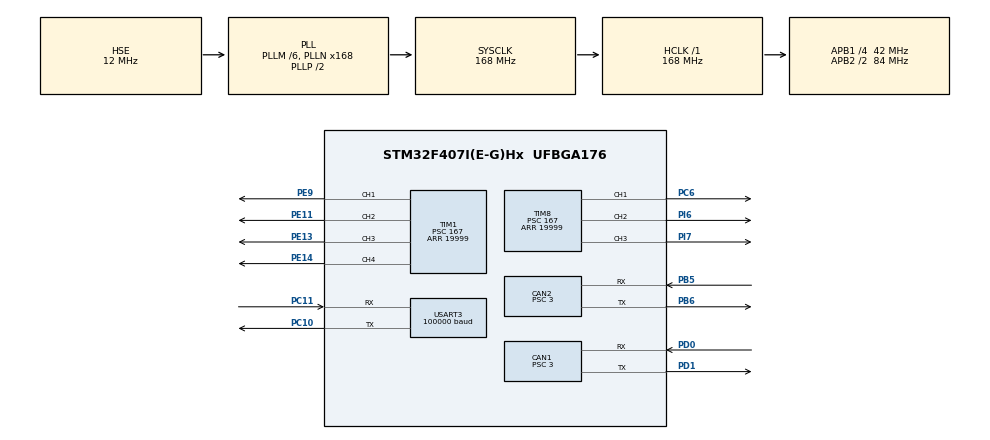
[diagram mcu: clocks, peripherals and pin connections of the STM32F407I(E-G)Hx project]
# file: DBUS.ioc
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CAN1.BS1=CAN_BS1_10TQ
CAN1.BS2=CAN_BS2_3TQ
CAN1.CalculateTimeQuantum=71.42857142857143
CAN1.Prescaler=3
CAN2.BS1=CAN_BS1_10TQ
CAN2.BS2=CAN_BS2_3TQ
CAN2.CalculateTimeQuantum=71.42857142857143
CAN2.Prescaler=3
Dma.Request0=USART3_RX
Dma.USART3_RX.0.Direction=DMA_PERIPH_TO_MEMORY
Dma.USART3_RX.0.FIFOMode=DMA_FIFOMODE_DISABLE
Dma.USART3_RX.0.Instance=DMA1_Stream1
Dma.USART3_RX.0.MemDataAlignment=DMA_MDATAALIGN_BYTE
Dma.USART3_RX.0.MemInc=DMA_MINC_ENABLE
Dma.USART3_RX.0.Mode=DMA_CIRCULAR
Dma.USART3_RX.0.PeriphDataAlignment=DMA_PDATAALIGN_BYTE
Dma.USART3_RX.0.PeriphInc=DMA_PINC_DISABLE
Dma.USART3_RX.0.Priority=DMA_PRIORITY_VERY_HIGH
FREERTOS.Tasks01=defaultTask,0,128,StartDefaultTask,Default,NULL,Dynamic,NULL,NULL
Mcu.Family=STM32F4
Mcu.Name=STM32F407I(E-G)Hx
Mcu.Package=UFBGA176
NVIC.CAN1_RX0_IRQn=true\:5\:0\:false\:false\:true\:true\:true\:true
NVIC.CAN2_RX0_IRQn=true\:5\:0\:false\:false\:true\:true\:true\:true
NVIC.DMA1_Stream1_IRQn=true\:5\:0\:false\:false\:true\:true\:false\:true
NVIC.PriorityGroup=NVIC_PRIORITYGROUP_4
NVIC.TIM2_IRQn=true\:0\:0\:false\:false\:true\:false\:false\:true
NVIC.TimeBase=TIM2_IRQn
NVIC.TimeBaseIP=TIM2
NVIC.USART3_IRQn=true\:5\:0\:false\:false\:false\:true\:true\:false
PA13.Mode=Serial_Wire
PA13.Signal=SYS_JTMS-SWDIO
PA14.Mode=Serial_Wire
PA14.Signal=SYS_JTCK-SWCLK
PB5.Mode=Slave
PB5.Signal=CAN2_RX
PB6.Mode=Slave
PB6.Signal=CAN2_TX
PC10.Mode=Asynchronous
PC10.Signal=USART3_TX
PC11.Mode=Asynchronous
PC11.Signal=USART3_RX
PC6.GPIO_PuPd=GPIO_PULLUP
PC6.GPIO_Speed=GPIO_SPEED_FREQ_HIGH
PC6.Signal=S_TIM8_CH1
PD0.Mode=Master
PD0.Signal=CAN1_RX
PD1.Mode=Master
PD1.Signal=CAN1_TX
PE11.GPIO_PuPd=GPIO_PULLUP
PE11.GPIO_Speed=GPIO_SPEED_FREQ_HIGH
PE11.Signal=S_TIM1_CH2
PE13.GPIO_PuPd=GPIO_PULLUP
PE13.GPIO_Speed=GPIO_SPEED_FREQ_HIGH
PE13.Signal=S_TIM1_CH3
PE14.GPIO_PuPd=GPIO_PULLUP
PE14.GPIO_Speed=GPIO_SPEED_FREQ_HIGH
PE14.Signal=S_TIM1_CH4
PE9.GPIO_PuPd=GPIO_PULLUP
PE9.GPIO_Speed=GPIO_SPEED_FREQ_HIGH
PE9.Signal=S_TIM1_CH1
PH0-OSC_IN.Mode=HSE-External-Oscillator
PH0-OSC_IN.Signal=RCC_OSC_IN
PH1-OSC_OUT.Mode=HSE-External-Oscillator
PH1-OSC_OUT.Signal=RCC_OSC_OUT
PI6.GPIO_PuPd=GPIO_PULLUP
PI6.GPIO_Speed=GPIO_SPEED_FREQ_HIGH
PI6.Signal=S_TIM8_CH2
PI7.GPIO_PuPd=GPIO_PULLUP
PI7.GPIO_Speed=GPIO_SPEED_FREQ_HIGH
PI7.Signal=S_TIM8_CH3
ProjectManager.HeapSize=0x2000
ProjectManager.StackSize=0x2000
ProjectManager.TargetToolchain=MDK-ARM V5
RCC.48MHZClocksFreq_Value=48000000
RCC.AHBFreq_Value=168000000
RCC.APB1CLKDivider=RCC_HCLK_DIV4
RCC.APB1Freq_Value=42000000
RCC.APB1TimFreq_Value=84000000
RCC.APB2CLKDivider=RCC_HCLK_DIV2
RCC.APB2Freq_Value=84000000
RCC.APB2TimFreq_Value=168000000
RCC.CortexFreq_Value=168000000
RCC.HCLKFreq_Value=168000000
RCC.HSE_VALUE=12000000
RCC.HSI_VALUE=16000000
RCC.LSE_VALUE=32768
RCC.PLLM=6
RCC.PLLN=168
RCC.PLLQ=7
RCC.PLLSourceVirtual=RCC_PLLSOURCE_HSE
RCC.RCC_RTC_Clock_SourceVirtual=RCC_RTCCLKSOURCE_HSE_DIV30
RCC.RCC_RTC_Clock_Source_FROM_HSE=RCC_RTCCLKSOURCE_HSE_DIV30
RCC.SYSCLKFreq_VALUE=168000000
RCC.SYSCLKSource=RCC_SYSCLKSOURCE_PLLCLK
RCC.VCOOutputFreq_Value=336000000
SH.S_TIM1_CH1.0=TIM1_CH1,PWM Generation1 CH1
SH.S_TIM1_CH2.0=TIM1_CH2,PWM Generation2 CH2
SH.S_TIM1_CH3.0=TIM1_CH3,PWM Generation3 CH3
SH.S_TIM1_CH4.0=TIM1_CH4,PWM Generation4 CH4
SH.S_TIM8_CH1.0=TIM8_CH1,PWM Generation1 CH1
SH.S_TIM8_CH2.0=TIM8_CH2,PWM Generation2 CH2
SH.S_TIM8_CH3.0=TIM8_CH3,PWM Generation3 CH3
TIM1.Channel-PWM\ Generation1\ CH1=TIM_CHANNEL_1
TIM1.Channel-PWM\ Generation2\ CH2=TIM_CHANNEL_2
TIM1.Channel-PWM\ Generation3\ CH3=TIM_CHANNEL_3
TIM1.Channel-PWM\ Generation4\ CH4=TIM_CHANNEL_4
TIM1.Period=19999
TIM1.Prescaler=167
TIM1.Pulse-PWM\ Generation1\ CH1=2000
TIM1.Pulse-PWM\ Generation2\ CH2=2000
TIM1.Pulse-PWM\ Generation3\ CH3=2000
TIM1.Pulse-PWM\ Generation4\ CH4=2000
TIM8.Channel-PWM\ Generation1\ CH1=TIM_CHANNEL_1
TIM8.Channel-PWM\ Generation2\ CH2=TIM_CHANNEL_2
TIM8.Channel-PWM\ Generation3\ CH3=TIM_CHANNEL_3
TIM8.Period=19999
TIM8.Prescaler=167
TIM8.Pulse-PWM\ Generation1\ CH1=2000
TIM8.Pulse-PWM\ Generation2\ CH2=2000
TIM8.Pulse-PWM\ Generation3\ CH3=2000
USART3.BaudRate=100000
USART3.Parity=PARITY_EVEN
USART3.VirtualMode=VM_ASYNC
USART3.WordLength=WORDLENGTH_9B
VP_FREERTOS_VS_CMSIS_V1.Mode=CMSIS_V1
VP_SYS_VS_tim2.Mode=TIM2
VP_TIM1_VS_ClockSourceINT.Mode=Internal
VP_TIM8_VS_ClockSourceINT.Mode=Internal
board=custom

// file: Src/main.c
/* USER CODE BEGIN Header */
/**
  ******************************************************************************
  * @file           : main.c
  * @brief          : Main program body
  ******************************************************************************
  * @attention
  *
  * <h2><center>&copy; Copyright (c) 2020 STMicroelectronics.
  * All rights reserved.</center></h2>
  *
  * This software component is licensed by ST under BSD 3-Clause license,
  * the "License"; You may not use this file except in compliance with the
  * License. You may obtain a copy of the License at:
  *                        opensource.org/licenses/BSD-3-Clause
  *
  ******************************************************************************
  */
/* USER CODE END Header */

#include "main.h"
#include "cmsis_os.h"
#include "can.h"
#include "dma.h"
#include "tim.h"
#include "usart.h"
#include "gpio.h"

/* USER CODE BEGIN Includes */
#include "bsp_can.h"
#include "remote_control.h"
#include "chassis_task.h"
/* USER CODE END Includes */

void SystemClock_Config(void);
void MX_FREERTOS_Init(void);

int main(void)
{

  /* MCU Configuration--------------------------------------------------------*/

  /* Reset of all peripherals, Initializes the Flash interface and the Systick. */
  HAL_Init();

  /* Configure the system clock */
  SystemClock_Config();

  /* Initialize all configured peripherals */
  MX_GPIO_Init();
  MX_DMA_Init();
  MX_TIM8_Init();
  MX_TIM1_Init();
  MX_USART3_UART_Init();
  MX_CAN1_Init();
  MX_CAN2_Init();
  /* USER CODE BEGIN 2 */
    can_filter_init();
    remote_control_init();
  /* USER CODE END 2 */

  /* Call init function for freertos objects (in freertos.c) */
  MX_FREERTOS_Init();
  /* Start scheduler */
  osKernelStart();

  /* We should never get here as control is now taken by the scheduler */
  /* Infinite loop */
  while (1)
  {

  }
}

void SystemClock_Config(void)
{
  RCC_OscInitTypeDef RCC_OscInitStruct = {0};
  RCC_ClkInitTypeDef RCC_ClkInitStruct = {0};

  /** Configure the main internal regulator output voltage
  */
  __HAL_RCC_PWR_CLK_ENABLE();
  __HAL_PWR_VOLTAGESCALING_CONFIG(PWR_REGULATOR_VOLTAGE_SCALE1);
  /** Initializes the CPU, AHB and APB busses clocks
  */
  RCC_OscInitStruct.OscillatorType = RCC_OSCILLATORTYPE_HSE;
  RCC_OscInitStruct.HSEState = RCC_HSE_ON;
  RCC_OscInitStruct.PLL.PLLState = RCC_PLL_ON;
  RCC_OscInitStruct.PLL.PLLSource = RCC_PLLSOURCE_HSE;
  RCC_OscInitStruct.PLL.PLLM = 6;
  RCC_OscInitStruct.PLL.PLLN = 168;
  RCC_OscInitStruct.PLL.PLLP = RCC_PLLP_DIV2;
  RCC_OscInitStruct.PLL.PLLQ = 7;
  if (HAL_RCC_OscConfig(&RCC_OscInitStruct) != HAL_OK)
  {
    Error_Handler();
  }
  /** Initializes the CPU, AHB and APB busses clocks
  */
  RCC_ClkInitStruct.ClockType = RCC_CLOCKTYPE_HCLK|RCC_CLOCKTYPE_SYSCLK
                              |RCC_CLOCKTYPE_PCLK1|RCC_CLOCKTYPE_PCLK2;
  RCC_ClkInitStruct.SYSCLKSource = RCC_SYSCLKSOURCE_PLLCLK;
  RCC_ClkInitStruct.AHBCLKDivider = RCC_SYSCLK_DIV1;
  RCC_ClkInitStruct.APB1CLKDivider = RCC_HCLK_DIV4;
  RCC_ClkInitStruct.APB2CLKDivider = RCC_HCLK_DIV2;

  if (HAL_RCC_ClockConfig(&RCC_ClkInitStruct, FLASH_LATENCY_5) != HAL_OK)
  {
    Error_Handler();
  }
}

 /**
  * @brief  Period elapsed callback in non blocking mode
  * @note   This function is called  when TIM2 interrupt took place, inside
  * HAL_TIM_IRQHandler(). It makes a direct call to HAL_IncTick() to increment
  * a global variable "uwTick" used as application time base.
  * @param  htim : TIM handle
  * @retval None
  */
void HAL_TIM_PeriodElapsedCallback(TIM_HandleTypeDef *htim)
{
  if (htim->Instance == TIM2) {
    HAL_IncTick();
  }
}

void Error_Handler(void)
{
}

/************************ (C) COPYRIGHT STMicroelectronics *****END OF FILE****/

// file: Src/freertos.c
/* USER CODE BEGIN Header */
/**
  ******************************************************************************
  * File Name          : freertos.c
  * Description        : Code for freertos applications
  ******************************************************************************
  * @attention
  *
  * <h2><center>&copy; Copyright (c) 2020 STMicroelectronics.
  * All rights reserved.</center></h2>
  *
  * This software component is licensed by ST under Ultimate Liberty license
  * SLA0044, the "License"; You may not use this file except in compliance with
  * the License. You may obtain a copy of the License at:
  *                             www.st.com/SLA0044
  *
  ******************************************************************************
  */
/* USER CODE END Header */

#include "FreeRTOS.h"
#include "task.h"
#include "main.h"
#include "cmsis_os.h"

/* USER CODE BEGIN Includes */

#include "chassis_task.h"

/* USER CODE END Includes */

/* USER CODE BEGIN PTD */
osThreadId chassisTaskHandle;
/* USER CODE END PTD */

osThreadId defaultTaskHandle;

void StartDefaultTask(void const * argument);

void MX_FREERTOS_Init(void); /* (MISRA C 2004 rule 8.1) */

/* GetIdleTaskMemory prototype (linked to static allocation support) */
void vApplicationGetIdleTaskMemory( StaticTask_t **ppxIdleTaskTCBBuffer, StackType_t **ppxIdleTaskStackBuffer, uint32_t *pulIdleTaskStackSize );

/* USER CODE BEGIN GET_IDLE_TASK_MEMORY */
static StaticTask_t xIdleTaskTCBBuffer;
static StackType_t xIdleStack[configMINIMAL_STACK_SIZE];

void vApplicationGetIdleTaskMemory( StaticTask_t **ppxIdleTaskTCBBuffer, StackType_t **ppxIdleTaskStackBuffer, uint32_t *pulIdleTaskStackSize )
{
  *ppxIdleTaskTCBBuffer = &xIdleTaskTCBBuffer;
  *ppxIdleTaskStackBuffer = &xIdleStack[0];
  *pulIdleTaskStackSize = configMINIMAL_STACK_SIZE;
  /* place for user code */
}
/* USER CODE END GET_IDLE_TASK_MEMORY */

void MX_FREERTOS_Init(void) {

  /* Create the thread(s) */
  /* definition and creation of defaultTask */
  osThreadDef(defaultTask, StartDefaultTask, osPriorityNormal, 0, 128);
  defaultTaskHandle = osThreadCreate(osThread(defaultTask), NULL);

  /* USER CODE BEGIN RTOS_THREADS */
  /* add threads, ... */
	    osThreadDef(ChassisTask, chassis_task, osPriorityAboveNormal, 0, 512);
			chassisTaskHandle = osThreadCreate(osThread(ChassisTask), NULL);
  /* USER CODE END RTOS_THREADS */

}

void StartDefaultTask(void const * argument)
{
  for(;;)
  {
    osDelay(1);
  }
}

/************************ (C) COPYRIGHT STMicroelectronics *****END OF FILE****/
